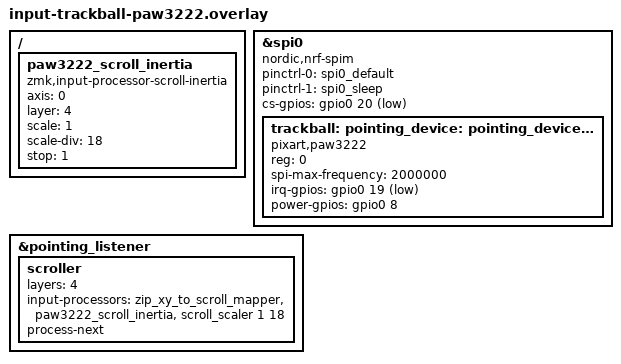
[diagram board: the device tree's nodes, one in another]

/ {
    paw3222_scroll_inertia: paw3222_scroll_inertia {
        compatible = "zmk,input-processor-scroll-inertia";
        #input-processor-cells = <0>;

        /* axis = 0: both axes, matching the free vertical/horizontal
         * scroll already produced by zip_xy_to_scroll_mapper below. */
        axis = <0>;
        layer = <4>;

        /* Must match the &scroll_scaler args downstream. */
        scale = <1>;
        scale-div = <18>;

        /* Lowered from the default (7) to match our small scale/scale-div
         * ratio: output frequency at cutoff = stop * scale * 125 / scale-div. */
        stop = <1>;
    };
};

&spi0 {
    status = "okay";
    compatible = "nordic,nrf-spim";
    pinctrl-0 = <&spi0_default>;
    pinctrl-1 = <&spi0_sleep>;
    pinctrl-names = "default", "sleep";
    cs-gpios = <&gpio0 20 GPIO_ACTIVE_LOW>;

    trackball: pointing_device: pointing_device@0 {
        status = "okay";
        compatible = "pixart,paw3222";
        reg = <0>;
        spi-max-frequency = <2000000>;
        irq-gpios = <&gpio0 19 GPIO_ACTIVE_LOW>;
        power-gpios = <&gpio0 8 (GPIO_ACTIVE_HIGH | NRF_GPIO_DRIVE_H0H1)>;
    };
};

&pointing_listener {
    scroller {
        layers = <4>;
        input-processors =
            <&zip_xy_to_scroll_mapper>,
            <&paw3222_scroll_inertia>,
            <&scroll_scaler 1 18>;
        process-next;
    };
};
